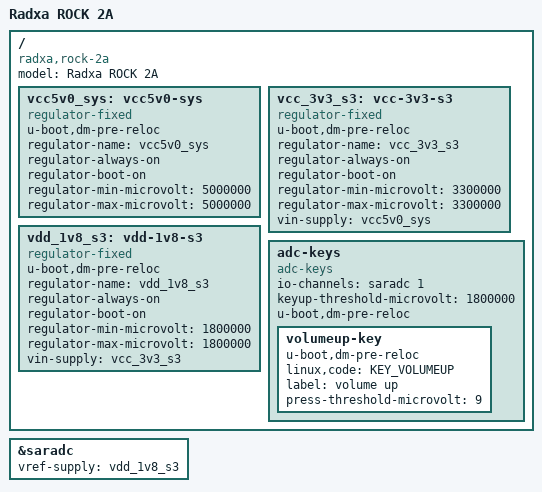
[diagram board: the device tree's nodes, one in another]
/*
 * SPDX-License-Identifier:     GPL-2.0+
 *
 * (C) Copyright 2020 Rockchip Electronics Co., Ltd
 * (C) Copyright 2024 Radxa Limited
 *
 */

/dts-v1/;
#include "rk3528.dtsi"
#include "rk3528-u-boot.dtsi"
#include <dt-bindings/input/input.h>

/ {
	model = "Radxa ROCK 2A";
	compatible = "radxa,rock-2a", "rockchip,rk3528";

	vcc5v0_sys: vcc5v0-sys {
		u-boot,dm-pre-reloc;
		compatible = "regulator-fixed";
		regulator-name = "vcc5v0_sys";
		regulator-always-on;
		regulator-boot-on;
		regulator-min-microvolt = <5000000>;
		regulator-max-microvolt = <5000000>;
	};

	vcc_3v3_s3: vcc-3v3-s3 {
		u-boot,dm-pre-reloc;
		compatible = "regulator-fixed";
		regulator-name = "vcc_3v3_s3";
		regulator-always-on;
		regulator-boot-on;
		regulator-min-microvolt = <3300000>;
		regulator-max-microvolt = <3300000>;
		vin-supply = <&vcc5v0_sys>;
	};

	vdd_1v8_s3: vdd-1v8-s3 {
		u-boot,dm-pre-reloc;
		compatible = "regulator-fixed";
		regulator-name = "vdd_1v8_s3";
		regulator-always-on;
		regulator-boot-on;
		regulator-min-microvolt = <1800000>;
		regulator-max-microvolt = <1800000>;
		vin-supply = <&vcc_3v3_s3>;
	};

	adc-keys {
		compatible = "adc-keys";
		io-channels = <&saradc 1>;
		io-channel-names = "buttons";
		keyup-threshold-microvolt = <1800000>;
		u-boot,dm-pre-reloc;
		status = "okay";

		volumeup-key {
			u-boot,dm-pre-reloc;
			linux,code = <KEY_VOLUMEUP>;
			label = "volume up";
			press-threshold-microvolt = <9>;
		};
	};
};

&saradc {
	vref-supply = <&vdd_1v8_s3>;
	status = "okay";
};
